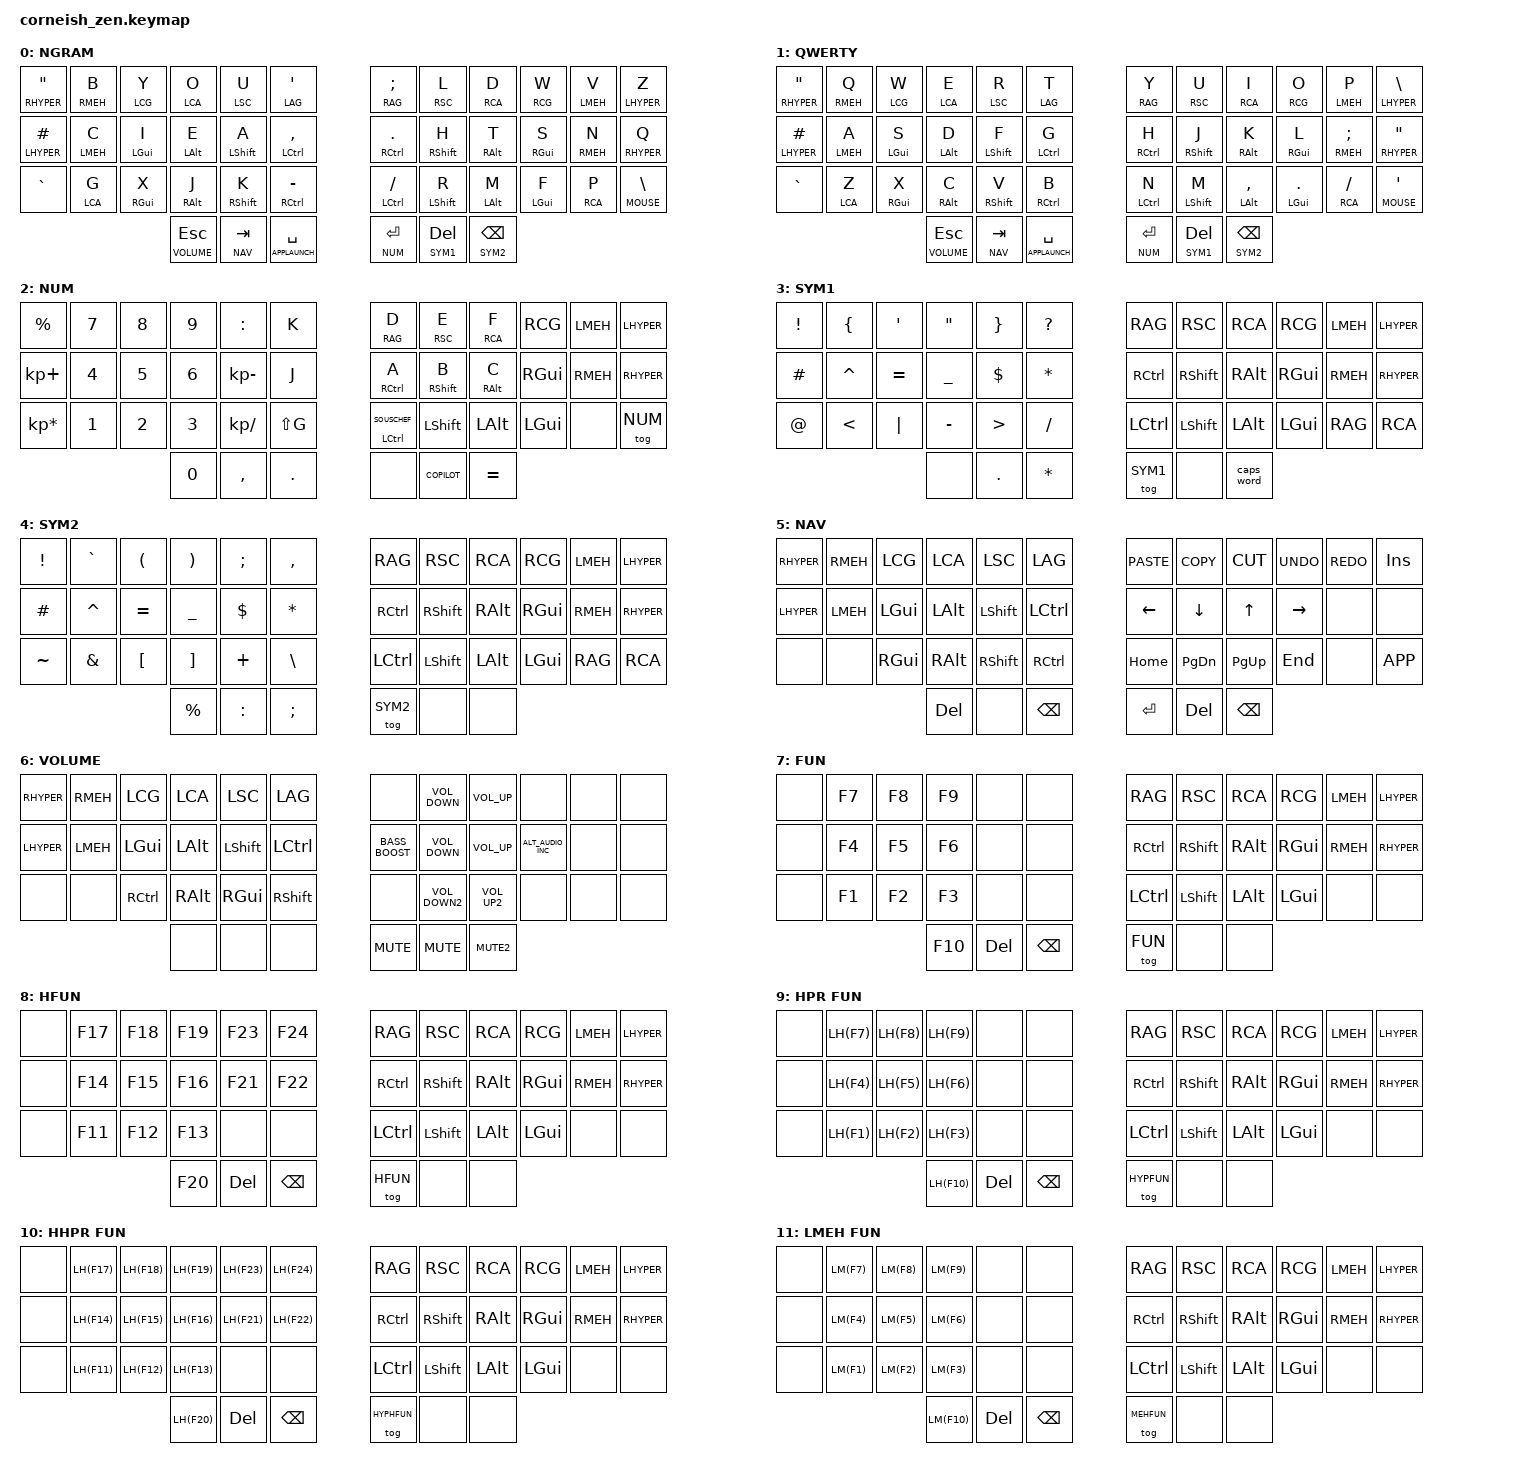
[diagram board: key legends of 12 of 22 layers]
/*
*
* Copyright (c) 2024  Hans Kruse
* Based on a configuration (c) 2023 Darryl deHaan
* SPDX-License-Identifier: MIT
*
*/

#include <behaviors.dtsi>
#include <dt-bindings/zmk/keys.h>
#include <dt-bindings/zmk/bt.h>
#include <dt-bindings/zmk/mouse.h>
#include <dt-bindings/zmk/outputs.h>
#include <dt-bindings/zmk/ext_power.h>
#include "numpad_extra_keys.h"
#include "consumer_extra_keys.h"
#include "custom_modifiers.h"

#define COPILOT  LSGK(F23)
#define SOUSCHEF RCAK(F24)


// layers
#define DEFAULT         0
#define NGRAM           0
#define QWERTY          1
#define NUM             2
#define SYM1            3
#define SYM2            4
#define NAV             5
#define VOLUME          6 
#define FUN             7
#define HFUN            8
#define HYPFUN          9
#define HYPHFUN        10
#define MEHFUN         11
#define MEHHFUN        12
#define MOUSE          13
#define CONFIG         14
#define POWER          15
#define DISPLAY        16
#define INTERNATIONAL  17
#define LANGUAGE       18
#define APPLAUNCH      19
#define CONSUMER       20
#define EMPTYLAYER     21

/ {
  chosen {
    zmk,matrix_transform = &default_transform;
    //zmk,matrix_transform = &five_column_transform;
  };
};

/*
 * Key numbering cheat sheet:
 * 
 * 0     1  2  3  4  5    6  7  8  9  10 11
 * TAB   Q  W  E  R  T    Y  U  I  O  P  BKSP
 * 
 * 12    13 14 15 16 17   18 19 20 21 22 23
 * Ctrl  A  S  D  F  G    H  J  K  L  ;  SQT
 *  
 * 24    25 26 27 28 29   30 31 32 33 34 35
 * Shift Z  X  C  V  B    N  M  ,  .  /  ESQ
 *
 *          36  37 38     39     40   41
 *          Win UP SPC    ENTER  DOWN ALT
 */
 
#define KEYS_L 0 1 2 3 4 5 12 13 14 15 16 17 24 25 26 27 28 29
#define KEYS_R 5 6 8 9 10 11 18 19 20 21 22 23 30 31 32 33 34 35
#define THUMBS_L 36 37 38
#define THUMBS_R 39 40 41

#define HM_TAPPING_TERM 200
#define HM_TAPPING_TERM_FAST 175
#define HM_PRIOR_IDLE 125
#define HM_QUICK_TAP 150

 / {
    	combos {
        	compatible = "zmk,combos";

		combo_symbol1 {
            		layers = <NGRAM QWERTY SYM1>;
            		timeout-ms = <25>;
            		key-positions = <39 40>;
            		bindings = <&tog SYM1>;
        	};

		combo_symbol2 {
            		layers = <NGRAM QWERTY SYM2>;
            		timeout-ms = <25>;
            		key-positions = <39 41>;
            		bindings = <&tog SYM2>;
        	};

		combo_num {
            		layers = <NGRAM QWERTY NUM>;
            		timeout-ms = <25>;
            		key-positions = <39 35>;
            		bindings = <&tog NUM>;
        	};

		combo_config {
            		layers = <NGRAM QWERTY CONFIG>;
            		timeout-ms = <25>;
            		key-positions = <24 35>;
            		bindings = <&tog CONFIG>;
        	};

		combo_volume {
            		layers = <NGRAM QWERTY VOLUME>;
            		timeout-ms = <25>;
            		key-positions = <24 11>;
            		bindings = <&tog VOLUME>;
        	};

		combo_display {
            		layers = <NGRAM QWERTY DISPLAY>;
            		timeout-ms = <25>;
            		key-positions = <24 6>;
            		bindings = <&tog DISPLAY>;
        	};

		combo_language {
            		layers = <NGRAM QWERTY LANGUAGE>;
            		timeout-ms = <25>;
            		key-positions = <0 11>;
            		bindings = <&tog LANGUAGE>;
        	};

		combo_international {
            		layers = <NGRAM QWERTY INTERNATIONAL>;
            		timeout-ms = <25>;
            		key-positions = <0 35>;
            		bindings = <&tog INTERNATIONAL>;
        	};

		combo_function_keys {
            		layers = <NGRAM QWERTY FUN>;
            		timeout-ms = <25>;
            		key-positions = <0 30>;
            		bindings = <&tog FUN>;
        	};

		combo_high_function_keys {
            		layers = <NGRAM QWERTY HFUN>;
            		timeout-ms = <25>;
            		key-positions = <0 18>;
            		bindings = <&tog HFUN>;
        	};

		combo_hyper_function_keys {
            		layers = <NGRAM QWERTY HYPFUN>;
            		timeout-ms = <25>;
            		key-positions = <12 31>;
            		bindings = <&tog HYPFUN>;
        	};

		combo_hyper_high_function_keys {
            		layers = <NGRAM QWERTY HYPHFUN>;
            		timeout-ms = <25>;
            		key-positions = <12 19>;
            		bindings = <&tog HYPHFUN>;
        	};

		combo_meh_function_keys {
            		layers = <NGRAM QWERTY MEHFUN>;
            		timeout-ms = <25>;
            		key-positions = <24 32>;
            		bindings = <&tog MEHFUN>;
        	};

		combo_meh_high_function_keys {
            		layers = <NGRAM QWERTY MEHHFUN>;
            		timeout-ms = <25>;
            		key-positions = <24 20>;
            		bindings = <&tog MEHHFUN>;
        	};

    	};
	behaviors {
		hl: homerow_mods_left {
			compatible = "zmk,behavior-hold-tap";
			#binding-cells = <2>;
			bindings = <&kp>, <&kp>;
			flavor = "balanced";
			tapping-term-ms = <HM_TAPPING_TERM_FAST>;
			quick-tap-ms = <HM_QUICK_TAP>;
			require-prior-idle-ms = <HM_PRIOR_IDLE>;
			hold-trigger-key-positions = <KEYS_R THUMBS_R>;
	  	};
		hr: homerow_mods_right {
			compatible = "zmk,behavior-hold-tap";
			#binding-cells = <2>;
			bindings = <&kp>, <&kp>;
			flavor = "balanced";
			tapping-term-ms = <HM_TAPPING_TERM_FAST>;
			quick-tap-ms = <HM_QUICK_TAP>;
			require-prior-idle-ms = <HM_PRIOR_IDLE>;
			hold-trigger-key-positions = <KEYS_L THUMBS_L>;
	  	};

	};

        keymap {
                compatible = "zmk,keymap";

                default_layer {
                        label = "NGRAM";
// ---------------------------------------------------------------------------------------------------------------------------------------------------------------------------------------------------------------------------------------------
// |          DQT   |         B  |            Y  |           O   |            U   |               SQT   |                       |             SEMI |            L   |            D    |              W  |            V  |            Z         |
// |          HASH  |         C  |            I  |           E   |            A   |               COMMA |                       |             DOT  |            H   |            T    |              S  |            N  |            Q         |
// |          GRAVE |         G  |            X  |           J   |            K   |               MINUS |                       |             FSLH |            R   |            M    |              F  |            P  |            BACKSLASH |       
//                                               |           ESC |            TAB |               SPACE |                       |             RET  |            DEL |            BSPC |
                        bindings = <
   &hl RHYPER DQT    &hl RMEH B   &hl LCG     Y    &hl LCA    O    &hl LSC    U     &hl LAG       SQT                             &hr RAG     SEMI   &hr RSC    L     &hr RCA    D      &hr RCG      W    &hr LMEH   V    &hr LHYPER Z 
   &hl LHYPER HASH   &hl LMEH C   &hl LGUI    I    &hl LALT   E    &hl LSHFT  A     &hl LCTRL     COMMA                           &hr RCTRL   DOT    &hr RSHFT  H     &hr RALT   T      &hr RGUI     S    &hr RMEH   N    &hr RHYPER Q
   &kp        GRAVE  &hl LCA  G   &hl RGUI    X    &hl RALT   J    &hl RSHFT  K     &hl RCTRL     MINUS                           &hr LCTRL   FSLH   &hr LSHFT  R     &hr LALT   M      &hr LGUI     F    &hr RCA    P    &lt MOUSE  BACKSLASH 
                                                   &lt VOLUME ESC  &lt NAV    TAB   &lt APPLAUNCH SPACE                           &lt NUM     RET    &lt SYM1   DEL   &lt SYM2   BSPC 
                        >;
                };

                qwerty_layer {
                        label = "QWERTY";
// ------------------------------------------------------------------------------------------------------------------------------------------------------------------------------------------------------------------------------------------
// |          DQT   |         Q  |            W  |           E   |            R   |               T     |                       |             Y   |            U   |            I    |              O  |            P  |            \        |
// |          HASH  |         A  |            S  |           D   |            F   |               G     |                       |             H   |            J   |            K    |              L  |            ;  |            "        |
// |          GRAVE |         Z  |            X  |           C   |            V   |               B     |                       |             N   |            M   |            ,    |              .  |            /  |            '        |       
//                                               |           ESC |            TAB |               SPACE |                       |             RET |            DEL |            BSPC |
                        bindings = <
   &hl RHYPER DQT    &hl RMEH Q   &hl LCG     W    &hl LCA    E    &hl LSC    R     &hl LAG       T                               &hr RAG     Y     &hr RSC    U     &hr RCA    I      &hr RCG      O    &hr LMEH   P    &hr LHYPER BACKSLASH
   &hl LHYPER HASH   &hl LMEH A   &hl LGUI    S    &hl LALT   D    &hl LSHFT  F     &hl LCTRL     G                               &hr RCTRL   H     &hr RSHFT  J     &hr RALT   K      &hr RGUI     L    &hr RMEH   SEMI &hr RHYPER DQT
   &kp        GRAVE  &hl LCA  Z   &hl RGUI    X    &hl RALT   C    &hl RSHFT  V     &hl RCTRL     B                               &hr LCTRL   N     &hr LSHFT  M     &hr LALT   COMMA  &hr LGUI     DOT  &hr RCA    FSLH &lt MOUSE  SQT 
                                                   &lt VOLUME ESC  &lt NAV    TAB   &lt APPLAUNCH SPACE                           &lt NUM     RET   &lt SYM1   DEL   &lt SYM2   BSPC 
                        >;
                };


                number_layer {
                        label = "NUM";
// ------------------------------------------------------------------------------------------------------------------------------------------------------------------------------------------------------------------------
// |   %           |     7        |     8        |     9        |     :        | k        |                                     |          D        |           E       |          F |           |      LMEH |    LHYPER  |
// |   +           |     4        |     5        |     6        |     -        | j        |                                     |          A        |           B       |          C |           |      RMEH |    RHYPER  |
// |   *           |     1        |     2        |     3        |     /        | G        |                                     |          SOUSCHEF |                   |            |           |           |            |
//                                               |     0        |     ,        | .        |                                     |                   |           COPILOT |          = |
                            bindings = <
   &kp PERCENT       &kp NUMBER_7   &kp NUMBER_8   &kp NUMBER_9   &kp COLON      &kp K                                            &mt RAG   D          &mt RSC   E          &mt RCA  F    &kp RCG     &kp LMEH  &kp LHYPER
   &kp KP_PLUS       &kp NUMBER_4   &kp NUMBER_5   &kp NUMBER_6   &kp KP_MINUS   &kp J                                            &mt RCTRL A          &mt RSHFT B          &mt RALT C    &kp RGUI    &kp RMEH  &kp RHYPER
   &kp KP_ASTERISK   &kp NUMBER_1   &kp NUMBER_2   &kp NUMBER_3   &kp KP_SLASH   &kp LS(G)                                        &mt LCTRL SOUSCHEF   &kp LSHFT            &kp LALT      &kp LGUI    &none     &tog NUM
                                                   &kp NUMBER_0   &kp COMMA      &kp DOT                                          &none                &kp        COPILOT   &kp      EQL      
                        >;
                };

                symbols_layer1 {
                        label = "SYM1";
// ---------------------------------------------------------------------------------------------------------------------------------------------------------------------------------------------------------
// |   !    |     {    |     '    |     "     |     }    |      ?        |                                                      |      RAG    |     RSC   |      RCA  |     RCG   |     LMEH |     LHYPER  |
// |   #    |     ^    |     =    |     _     |     $    |      *        |                                                      |      RCTRL  |     RSHFT |      RALT |     RGUI  |     RMEH |     RHYPER  |
// |   @    |     <    |    "|"   |     -     |     >    |      /        |                                                      |      LCTRL  |     LSHFT |      LALT |     LGUI  |     RAG  |     RCA     |
//                                |           |     .    |      *        |                                                      |             |           | CAPS WORD |
                       bindings = <
   &kp EXCL   &kp LBRC   &kp SQT    &kp DQT     &kp RBRC    &kp QMARK                                                             &kp  RAG    &kp   RSC     &kp   RCA   &kp RCG     &kp LMEH   &kp LHYPER
   &kp HASH   &kp CARET  &kp EQUAL  &kp UNDER   &kp DOLLAR  &kp ASTERISK                                                          &kp  RCTRL  &kp   RSHFT   &kp   RALT  &kp RGUI    &kp RMEH   &kp RHYPER
   &kp AT     &kp LT     &kp PIPE   &kp MINUS   &kp GT      &kp SLASH                                                             &kp  LCTRL  &kp   LSHFT   &kp   LALT  &kp LGUI    &kp RAG    &kp RCA
                                    &none       &kp DOT     &kp ASTERISK                                                          &tog SYM1   &none         &caps_word      
                        >;
                };
                symbols_layer2 {
                        label = "SYM2";
// ----------------------------------------------------------------------------------------------------------------------------------------------------------------------------------------------------------
// |   !    |     `     |      (   |     )       |     ;      |     ,         |                                                 |      RAG    |       RSC   |       RCA  |     RCG   |    LMEH |    LHYPER  |
// |   #    |     ^     |     =    |     _       |     $      |     *         |                                                 |      RCTRL  |       RSHFT |       RALT |     RGUI  |    RMEH |    RHYPER  |
// |   ~    |     &     |     [    |     ]       |     +      |     \         |                                                 |      LCTRL  |       LSHFT |       LALT |     LGUI  |    RAG  |    RCA     |
//                                 |     %       |     :      |     ;         |                                                 |             |             |            |
                       bindings = <
   &kp EXCL   &kp GRAVE   &kp LPAR   &kp RPAR      &kp SEMI     &kp COMMA                                                         &kp  RAG      &kp   RSC     &kp   RCA    &kp RCG    &kp LMEH  &kp LHYPER
   &kp HASH   &kp CARET   &kp EQUAL  &kp UNDER     &kp DOLLAR   &kp ASTERISK                                                      &kp  RCTRL    &kp   RSHFT   &kp   RALT   &kp RGUI   &kp RMEH  &kp RHYPER
   &kp TILDE  &kp AMPS    &kp LBKT   &kp RBKT      &kp PLUS     &kp BACKSLASH                                                     &kp  LCTRL    &kp   LSHFT   &kp   LALT   &kp LGUI   &kp RAG   &kp RCA
                                     &kp PERCENT   &kp COLON    &kp SEMI                                                          &tog SYM2     &none         &none      
                        >;
                };

                nav_layer {
                        label = "NAV";
// --------------------------------------------------------------------------------------------------------------------------------------------------------------------------------------------------------------------------
// |       RHYPER  |       RMEH   |     LCG   |     LCA  |       LSC   |     LAG   |                                            |     PASTE   |     COPY      |     CUT     |     UNDO   |       REDO   |            INS    |
// |       LHYPER  |       LMEH   |     LGUI  |     LALT |       LSHFT |     LCTRL |                                            |     LEFT    |     DOWN      |     UP      |     RIGHT  |              |                   |
// |               |              |     RGUI  |     RALT |       RSHFT |     RCTRL |                                            |     HOME    |     PAGE_DOWN |     PAGE_UP |     END    |              |            K_APP  |       
//                                            |     DEL  |             |     BSPC  |                                            |     RET     |     DEL       |     BSPC    |
                        bindings = <
     &kp   RHYPER    &kp   RMEH     &kp LCG     &kp LCA    &kp   LSC     &kp LAG                                                  &kp K_PASTE   &kp K_COPY      &kp K_CUT     &kp K_UNDO   &kp   K_REDO   &kp        INS
     &kp   LHYPER    &kp   LMEH     &kp LGUI    &kp LALT   &kp   LSHFT   &kp LCTRL                                                &kp LEFT      &kp DOWN        &kp UP        &kp RIGHT    &none          &none
     &none           &none          &kp RGUI    &kp RALT   &kp   RSHFT   &kp RCTRL                                                &kp HOME      &kp PAGE_DOWN   &kp PAGE_UP   &kp END      &none          &kp        K_APP
                                                &kp DEL    &none         &kp BSPC                                                 &kp RET       &kp DEL         &kp BSPC      
                        >;
                };

                volume_layer {
                        label = "VOLUME";
// ----------------------------------------------------------------------------------------------------------------------------------------------------------------------------------------------------------------------------------
// |       RHYPER |      RMEH |     LCG   |       LCA  |       LSC   |     LAG   |                                              |                    |     K_VOLUME_DOWN  |     K_VOlUME_UP  |                       |              |                |
// |       LHYPER |      LMEH |     LGUI  |       LALT |       LSHFT |     LCTRL |                                              |       C_BASS_BOOST |     C_VOLUME_DOWN  |     C_VOLUME_UP  |       C_ALT_AUDIO_INC |              |                |
// |              |           |     RCTRL |       RALT |       RGUI  |     RSHFT |                                              |                    |     K_VOLUME_DOWN2 |     K_VOlUME_UP2 |                       |              |                |      
//                                        |            |             |           |                                              |       K_MUTE       |     C_MUTE         |     K_MUTE2      |
                        bindings = <
     &kp   RHYPER   &kp  RMEH   &kp LCG     &kp   LCA    &kp   LSC   &kp   LAG                                                    &none                &kp K_VOLUME_DOWN    &kp K_VOLUME_UP    &none                   &none  &none 
     &kp   LHYPER   &kp  LMEH   &kp LGUI    &kp   LALT   &kp   LSHFT &kp   LCTRL                                                  &kp   C_BASS_BOOST   &kp C_VOLUME_DOWN    &kp C_VOLUME_UP    &kp   C_ALT_AUDIO_INC   &none  &none
     &none          &none       &kp RCTRL   &kp   RALT   &kp   RGUI  &kp   RSHFT                                                  &none                &kp K_VOLUME_DOWN2   &kp K_VOLUME_UP2   &none                   &none  &none
                                            &none        &none       &none                                                        &kp   K_MUTE         &kp C_MUTE           &kp K_MUTE2
                        >;
                };

                fun_layer {
                        label = "FUN";
// --------------------------------------------------------------------------------------------------------------------------------------------------------------------------------------------------------------
// |       |     F7 |   F8 |     F9  |         |            |                                                                   |      RAG    |       RSC   |     RCA  |      RCG  |       LMEH |       LHYPER  |
// |       |     F4 |   F5 |     F6  |         |            |                                                                   |      RCTRL  |       RSHFT |     RALT |      RGUI |       RMEH |       RHYPER  |
// |       |     F1 |   F2 |     F3  |         |            |                                                                   |      LCTRL  |       LSHFT |     LALT |      LGUI |            |               |
//                         |     F10 |     DEL |       BSPC |                                                                   | tog  FUN    |             |          |
                         bindings = <
     &none   &kp F7 &kp F8 &kp   F9  &none       &none                                                                            &kp  RAG      &kp   RSC     &kp RCA     &kp RCG    &kp   LMEH   &kp   LHYPER
     &none   &kp F4 &kp F5 &kp   F6  &none       &none                                                                            &kp  RCTRL    &kp   RSHFT   &kp RALT    &kp RGUI   &kp   RMEH   &kp   RHYPER
     &none   &kp F1 &kp F2 &kp   F3  &none       &none                                                                            &kp  LCTRL    &kp   LSHFT   &kp LALT    &kp LGUI   &none        &none
                           &kp   F10 &kp   DEL   &kp   BSPC                                                                       &tog FUN      &none         &none     
                        >;
                };

                hfun_layer {
                        label = "HFUN";
// ----------------------------------------------------------------------------------------------------------------------------------------------------------------------------------------------------------------
// |       |     F17 |     F18 |       F19 |       F23  |       F24  |                                                          |      RAG    |       RSC   |       RCA  |      RCG  |       LMEH |       LHYPER  |
// |       |     F14 |     F15 |       F16 |       F21  |       F22  |                                                          |      RCTRL  |       RSHFT |       RALT |      RGUI |       RMEH |       RHYPER  |
// |       |     F11 |     F12 |       F13 |            |            |                                                          |      LCTRL  |       LSHFT |       LALT |      LGUI |            |               |
//                             |       F20 |        DEL |       BSPC |                                                          |  tog HFUN   |             |            |
                         bindings = <
     &none   &kp F17   &kp F18   &kp   F19   &kp   F23    &kp   F24                                                               &kp  RAG      &kp   RSC     &kp   RCA     &kp RCG    &kp   LMEH   &kp   LHYPER
     &none   &kp F14   &kp F15   &kp   F16   &kp   F21    &kp   F22                                                               &kp  RCTRL    &kp   RSHFT   &kp   RALT    &kp RGUI   &kp   RMEH   &kp   RHYPER
     &none   &kp F11   &kp F12   &kp   F13   &none        &none                                                                   &kp  LCTRL    &kp   LSHFT   &kp   LALT    &kp LGUI   &none        &none
                                 &kp   F20   &kp   DEL    &kp   BSPC                                                              &tog HFUN     &none         &none     
                        >;
                };

                hypfun_layer {
                        label = "HPR FUN";
// -----------------------------------------------------------------------------------------------------------------------------------------------------------------------------------------------------------------
// |       |        F7  |        F8  |        F9  |          |            |                                                     |       RAG    |       RSC   |       RCA  |      RCG  |       LMEH |       LHYPER  |
// |       |        F4  |        F5  |        F6  |          |            |                                                     |       RCTRL  |       RSHFT |       RALT |      RGUI |       RMEH |       RHYPER  |
// |       |        F1  |        F2  |        F3  |          |            |                                                     |       LCTRL  |       LSHFT |       LALT |      LGUI |            |               |
//                                   |        F10 |          |            |                                                     |              |             |            |
                         bindings = <
     &none   &kp LH(F7)   &kp LH(F8)   &kp LH(F9)   &none      &none                                                              &kp   RAG      &kp   RSC     &kp   RCA     &kp RCG    &kp   LMEH   &kp   LHYPER
     &none   &kp LH(F4)   &kp LH(F5)   &kp LH(F6)   &none      &none                                                              &kp   RCTRL    &kp   RSHFT   &kp   RALT    &kp RGUI   &kp   RMEH   &kp   RHYPER
     &none   &kp LH(F1)   &kp LH(F2)   &kp LH(F3)   &none      &none                                                              &kp   LCTRL    &kp   LSHFT   &kp   LALT    &kp LGUI   &none        &none
                                       &kp LH(F10)  &kp   DEL  &kp   BSPC                                                         &tog  HYPFUN   &none         &none     
                        >;
                };

                hyphfun_layer {
                        label = "HHPR FUN";
// ---------------------------------------------------------------------------------------------------------------------------------------------------------------------------------------------------------------
// |       |        F17  |        F18 |        F19 |          F23 |           F24 |                                             |       RAG     |      RSC   |     RCA  |      RCG  |       LMEH |       LHYPER  |
// |       |        F14  |        F15 |        F16 |          F21 |           F22 |                                             |       RCTRL   |      RSHFT |     RALT |      RGUI |       RMEH |       RHYPER  |
// |       |        F11  |        F12 |        F13 |              |               |                                             |       LCTRL   |      LSHFT |     LALT |      LGUI |            |               |
//                                    |        F20 |          DEL |        BSPC   |                                             | tog   HYPHFUN |            |          |
                         bindings = <
     &none   &kp LH(F17)   &kp LH(F18)  &kp LH(F19)   &kp   LH(F23)  &kp   LH(F24)                                                &kp  RAG        &kp   RSC     &kp RCA     &kp RCG    &kp   LMEH   &kp   LHYPER
     &none   &kp LH(F14)   &kp LH(F15)  &kp LH(F16)   &kp   LH(F21)  &kp   LH(F22)                                                &kp  RCTRL      &kp   RSHFT   &kp RALT    &kp RGUI   &kp   RMEH   &kp   RHYPER
     &none   &kp LH(F11)   &kp LH(F12)  &kp LH(F13)   &none          &none                                                        &kp  LCTRL      &kp   LSHFT   &kp LALT    &kp LGUI   &none        &none
                                        &kp LH(F20)   &kp   DEL      &kp   BSPC                                                   &tog HYPHFUN    &none         &none     
                        >;
                };

                mehfun_layer {
                        label = "LMEH FUN";
// -----------------------------------------------------------------------------------------------------------------------------------------------------------------------------------------------------------------
// |      |         F7  |        F8  |        F9   |           |           |                                                     |      RAG    |       RSC   |       RCA  |      RCG  |       LMEH |       LHYPER  |
// |      |         F4  |        F5  |        F6   |           |           |                                                     |      RCTRL  |       RSHFT |       RALT |      RGUI |       RMEH |       RHYPER  |
// |      |         F1  |        F2  |        F3   |           |           |                                                     |      LCTRL  |       LSHFT |       LALT |      LGUI |            |               |
//                                   |        F10  |       DEL |      BSPC |                                                     |  tog MEHFUN |             |            |
                         bindings = <
    &none    &kp LM(F7)   &kp LM(F8)   &kp LM(F9)    &none      &none                                                             &kp  RAG       &kp   RSC     &kp   RCA     &kp RCG    &kp   LMEH   &kp   LHYPER
    &none    &kp LM(F4)   &kp LM(F5)   &kp LM(F6)    &none      &none                                                             &kp  RCTRL     &kp   RSHFT   &kp   RALT    &kp RGUI   &kp   RMEH   &kp   RHYPER
    &none    &kp LM(F1)   &kp LM(F2)   &kp LM(F3)    &none      &none                                                             &kp  LCTRL     &kp   LSHFT   &kp   LALT    &kp LGUI   &none        &none
                                       &kp LM(F10)   &kp   DEL  &kp   BSPC                                                        &tog MEHFUN    &none         &none     
                        >;
                };

                mehhfun_layer {
                        label = "HLMEH FUN";
// ------------------------------------------------------------------------------------------------------------------------------------------------------------------------------------------------------------------- 
// |       |        F17  |        F18  |        F19  |          F23  |          F24  |                                          |       RAG     |       RSC    |       RCA  |      RCG  |       LMEH |       LHYPER  |
// |       |        F14  |        F15  |        F16  |          F21  |          F22  |                                          |       RCTRL   |       RSHFT  |       RALT |      RGUI |       RMEH |       RHYPER  |
// |       |        F11  |        F12  |        F13  |               |               |                                          |       LCTRL   |       LSHFT  |       LALT |      LGUI |            |               |
//                                     |        F20  |               |               |                                          |   tog MEHHFUN |              |            |
                         bindings = <
     &none   &kp LM(F17)   &kp LM(F18)   &kp LM(F19)   &kp   LM(F23)   &kp   LM(F24)                                              &kp  RAG        &kp   RSC     &kp   RCA     &kp RCG    &kp   LMEH   &kp   LHYPER
     &none   &kp LM(F14)   &kp LM(F15)   &kp LM(F16)   &kp   LM(F21)   &kp   LM(F22)                                              &kp  RCTRL      &kp   RSHFT   &kp   RALT    &kp RGUI   &kp   RMEH   &kp   RHYPER
     &none   &kp LM(F11)   &kp LM(F12)   &kp LM(F13)   &none           &none                                                      &kp  LCTRL      &kp   LSHFT   &kp   LALT    &kp LGUI   &none        &none
                                         &kp LM(F20)   &kp   DEL       &kp   BSPC                                                 &tog MEHHFUN    &none         &none     
                        >;
                };

                mouse_layer {
                        label = "MOUSE";
// ---------------------------------------------------------------------------------------------------------------------------------------------------------------------------------------------
// |        |         |            |          |         |            |                                                          |       |       |           |           |           |          |
// | LHYPER |         |      LGUI  |     LALT |   LSHFT | LCTRL      |                                                          |       |       |       MB1 |       MB3 |       MB4 |      MB5 |
// | LMEH   |         |      RGUI  |     RALT |   RSHFT | RCTRL      |                                                          |       |       |       MB2 |           |           |          |      
//                                 |          |         |            |                                                          |       |       |           |
                        bindings = <
   &none        &none  &none         &none      &none        &none                                                                &none   &none   &none       &none      &none       &none   
   &kp   LHYPER &none  &kp   LGUI    &kp LALT   &kp    LSHFT &kp   LCTRL                                                          &none   &none   &mkp  MB1   &mkp  MB3  &mkp   MB4  &mkp  MB5
   &kp   LMEH   &none  &kp   RGUI    &kp RALT   &kp    RSHFT &kp   RCTRL                                                          &none   &none   &mkp  MB2   &none      &none       &none
                            &none    &none       &none                                                                            &none   &none   &none      
                        >;
                };
                
                config_layer {
                        label = "CONFIG";
// -----------------------------------------------------------------------------------------------------------------------------------------------------------------------------------------------------------------------------------------
// | left reset     |       |        |               |               |                |                                         |      BT_CLR      |     BT_PRV      |     BT_NXT    |     BT_CLR_AL   |               | right reset       |
// | left bootloader|       |        |               |               |                |                                         |      BT_SEL 0    |     BT_SEL 1    |     BT_SEL 2  |     BT_SEL 3    |     BT_SEL 4  | right bootloader  | 
// | soft off       |       |        |               |               |       SOFT OFF |                                         |      BT_DISC 0   |     BT_DISC 1   |     BT_DISC 2 |     BIT_DISC 3  |     BT_DISC 4 |            EP_TOG |
//                                   |       OUT_USB |       OUT_BLE |       OUT_TOG  |                                         |      EP_TOG      |     EP_ON       |     EP_OFF    |
                         bindings = <
   &sys_reset  &none         &none     &none           &to   QWERTY    &to   NGRAM                                                &bt  BT_CLR        &bt BT_PRV        &bt BT_NXT      &bt BT_CLR_ALL    &none           &sys_reset 
   &bootloader &none         &none     &none           &none           &none                                                      &bt  BT_SEL 0      &bt BT_SEL 1      &bt BT_SEL 2    &bt BT_SEL 3      &bt BT_SEL 4    &bootloader
   &soft_off   &none         &none     &none           &none           &soft_off                                                  &bt  BT_DISC 0     &bt BT_DISC 1     &bt BT_DISC 2   &bt BT_DISC 3     &bt BT_DISC 4   &ext_power EP_TOG
                                       &out  OUT_USB   &out  OUT_BLE   &out  OUT_TOG                                              &tog CONFIG        &ext_power EP_ON  &ext_power EP_OFF      
                        >;
                };

                power_layer {
                        label = "POWER";
// --------------------------------------------------------------------------------------------------------------------------------------------------------------------------------------------------------
// |       |       |       |      |       |         |                                                                           |     C_RESET      |     K_POWER   |    C_POWER     |      |      |       |
// |       |       |       |      |       |         |                                                                           |     C_SLEEP_MODE |     K_SLEEP   |    C_SLEEP     |      |      |       | 
// |       |       |       |      |       |         |                                                                           |                  |               |                |      |      |       |
//                         |      |       |         |                                                                           |     K_LOCK       |     C_AL_LOCK |    C_AL_LOGOFF |
                         bindings = <
     &none   &none   &none  &none   &none   &none                                                                                 &kp C_RESET        &kp K_POWER    &kp K_POWER       &none  &none  &none 
     &none   &none   &none  &none   &none   &none                                                                                 &kp C_SLEEP_MODE   &kp K_SLEEP    &kp C_SLEEP       &none  &none  &none
     &none   &none   &none  &none   &none   &none                                                                                 &none              &none          &none             &none  &none  &none
                            &none   &none   &none                                                                                 &kp K_LOCK         &kp C_AL_LOCK  &kp C_AL_LOGOFF  
                        >;
                };



                display_layer {
                        label = "DISPLAY";
// -------------------------------------------------------------------------------------------------------------------------------------------------------------------------------------------------------------------------------------
// |       |       |       |       |       |       |                                                                            | toggle DISPLAY   |                  |                  |                  |                  |       |
// |       |       |       |       |       |       |                                                                            |       C_BRI_MIN  |        C_BRI_DEC |        C_BRI_INC |        C_BR_MAX  |       C_BRI_AUTO |       | 
// |       |       |       |       |       |       |                                                                            |                  |                  |                  |                  |                  |       |
//                         |       |       |       |                                                                            |       C_BKLT_TOG |        C_ASPECT  |        C_PIP     | 
                         bindings = <
     &none   &none   &none   &none   &none   &none                                                                                &tog  DISPLAY      &none              &none              &none              &none              &none 
     &none   &none   &none   &none   &none   &none                                                                                &kp   C_BRI_MIN    &kp    C_BRI_DEC   &kp    C_BRI_INC   &kp    C_BRI_MAX   &kp   C_BRI_AUTO   &none
     &none   &none   &none   &none   &none   &none                                                                                &none              &none              &none              &none              &none              &none
                             &none   &none   &none                                                                                &kp   C_BKLT_TOG   &kp    C_ASPECT    &kp    C_PIP 
                        >;
                };


                international_layer {
                        label = "INT";
// -----------------------------------------------------------------------------------------------------------------------------------------------------------------------------------------------------------------------
// |       |     INT7 |     INT8 |        INT9  |          |             |                                                      |       RAG         |        RSC    |      RCA  |      RCG  |       LMEH |       LHYPER  |
// |       |     INT4 |     INT5 |        INT6  |          |             |                                                      |       RCTRL       |        RSHFT  |      RALT |      RGUI |       RMEH |       RHYPER  |
// |       |     INT1 |     INT2 |        INT3  |          |             |                                                      |       LCTRL       |        LSHFT  |      LALT |      LGUI |            |               |
//                               |              |      TAB |       SPACE |                                                      |                   |               |           |
                         bindings = < 
     &none   &kp INT7   &kp INT8    &kp   INT9   &none       &none                                                                &kp   RAG            &kp   RSC     &kp   RCA     &kp RCG    &kp   LMEH   &kp   LHYPER
     &none   &kp INT4   &kp INT5    &kp   INT6   &none       &none                                                                &kp   RCTRL          &kp   RSHFT   &kp   RALT    &kp RGUI   &kp   RMEH   &kp   RHYPER
     &none   &kp INT1   &kp INT2    &kp   INT3   &none       &none                                                                &kp   LCTRL          &kp   LSHFT   &kp   LALT    &kp LGUI   &none        &none
                                    &none        &kp   TAB   &kp   SPACE                                                          &tog  INTERNATIONAL  &none         &none 
                        >;
                };

                language_layer {
                        label = "LANG";
// -------------------------------------------------------------------------------------------------------------------------------------------------------------------- ----------------------------------------------
// |       |     LANG7 |     LANG8 |       LANG9  |            |             |                                                  |       RAG      |       RSC   |       RCA  |      RCG  |       LMEH |       LHYPER  |
// |       |     LANG4 |     LANG5 |       LANG6  |            |             |                                                  |       RCTRL    |       RSHFT |       RALT |      RGUI |       RMEH |       RHYPER  |
// |       |     LANG1 |     LANG2 |       LANG3  |            |             |                                                  |       LCTRL    |       LSHFT |       LALT |      LGUI |            |               |
//                                 |              |        TAB |             |                                                  |                |             |       |
                         bindings = <
     &none   &kp LANG7   &kp LANG8   &kp   LANG9     &none       &none                                                            &kp   RAG        &kp   RSC     &kp   RCA     &kp RCG    &kp   LMEH   &kp   LHYPER
     &none   &kp LANG4   &kp LANG5   &kp   LANG6     &none       &none                                                            &kp   RCTRL      &kp   RSHFT   &kp   RALT    &kp RGUI   &kp   RMEH   &kp   RHYPER
     &none   &kp LANG1   &kp LANG2   &kp   LANG3     &none       &none                                                            &kp   LCTRL      &kp   LSHFT   &kp   LALT    &kp LGUI   &none        &none
                                     &none           &kp   TAB   &kp   SPACE                                                      &tog  LANGUAGE   &none         &none 
                        >;
                };

                application_launch_layer {
                        label = "APPL";
// -----------------------------------------------------------------------------------------------------------------------------------------------------------------------------------------------------------------------------------------------------------------------------------------------------------------------------------------------------------------
// |        C_AL_MY_COMPUTER |    C_AL_DOCUMENTS   |     C_AL_FILE_BROWSER |     C_AL_WWW                |     K_WWW             |      C_AL_CALCULATOR      |                        |     C_AL_IMAGE_BROWSER |     C_AL_NEWS         |     C_AL_TASK_MANAGER        |    C_AL_KEYBOARD_LAYOUT  |    C_AL_COMMAND_LINE                    |     C_AL_HELP         |
// |        C_AL_EMAIL       |    C_AL_CALENDAR    |     C_AL_CONTACTS     |     C_AL_INSTANT_MESSAGING  |     C_AL_NETWORK_CHAT |      C_AL_TEXT_EDITOR     |                        |     C_AL_AUDIO_BROWSER |     C_AL_VOICEMAIL    |     C_AL_AV_CAPTURE_PLAYBACK |    C_AL_THESAURUS        |    C_AL_TELEPHONY_DIALER                |     K_HELP            |
// |        C_AL_WORD        |    C_AL_SPREADSHEET |     C_AL_PRESENTATION |     C_AL_DATABASE           |     C_AL_JOURNAL      |      C_AL_GRAPHICS_EDITOR |                        |     C_AL_MOVIE_BROWSER |     C_AL_FINANCE      |     C_AL_SPELLCHECK          |    C_AL_GRAMMAR_CHECK    |    C_AL_CONTEXT_AWARE_DESKTOP_ASSISTANT |     C_AL_OEM_FEATURES |
//                                                 |     C_AL_PRESENTATION |     C_AL_PREV_TASK          |     C_AL_NEXT_TASK    |                           |                        |     C_AL_SCREEN_SAVER  |     C_AL_COMMAND_LINE |     C_AL_SELECT_TASK         |
                         bindings = <
   &kp      C_AL_MY_COMPUTER  &kp C_AL_DOCUMENTS     &kp C_AL_FILE_BROWSER   &kp C_AL_WWW                  &kp K_WWW               &kp  C_AL_CALCULATOR                                 &kp C_AL_IMAGE_BROWSER   &kp C_AL_NEWS           &kp C_AL_TASK_MANAGER         &kp C_AL_KEYBOARD_LAYOUT   &kp C_AL_CONTROL_PANEL                     &kp C_AL_HELP
   &mt LHYPER C_AL_EMAIL        &kp C_AL_CALENDAR      &kp C_AL_CONTACTS       &kp C_AL_INSTANT_MESSAGING    &kp C_AL_NETWORK_CHAT   &kp  C_AL_TEXT_EDITOR                                &kp C_AL_AUDIO_BROWSER   &kp C_AL_VOICEMAIL      &kp C_AL_AV_CAPTURE_PLAYBACK  &kp C_AL_THESAURUS         &kp C_AL_TELEPHONY_DIALER                  &kp K_HELP
   &mt LMEH C_AL_WORD         &kp C_AL_SPREADSHEET   &kp C_AL_PRESENTATION   &kp C_AL_DATABASE             &kp C_AL_JOURNAL        &kp  C_AL_GRAPHICS_EDITOR                            &kp C_AL_MOVIE_BROWSER   &kp C_AL_FINANCE        &kp C_AL_SPELLCHECK           &kp C_AL_GRAMMAR_CHECK     &kp C_AL_CONTEXT_AWARE_DESKTOP_ASSISTANT   &kp C_AL_OEM_FEATURES
                                                                             &kp C_AL_PREV_TASK            &kp C_AL_NEXT_TASK      &none                                                &kp C_AL_SCREEN_SAVER    &kp C_AL_COMMAND_LINE   &kp C_AL_SELECT_TASK 
                        >;
                };

                consumer_layer {
                        label = "CONSUMER";
// ----------------------------     ---------------------------------------------------------------------------------------------------
// |       |      |      |     |      |         |                                          |      |      |      |      |      |       |
// |       |      |      |     |      |         |                                          |      |      |      |      |      |       | 
// |       |      |      |     |      |         |                                          |      |      |      |      |      |       |
//                       |     |      |         |                                          |      |      |      |
                         bindings = <
   &kp   AT  &none       &none  &none  &none  &none                                          &none  &none  &none  &none  &none  &none 
   &none     &none       &none  &none  &none  &none                                          &none  &none  &none  &none  &none  &none
   &none     &none       &none  &none  &none  &none                                          &none  &none  &none  &none  &none  &none
                                &none  &none  &none                                          &none  &none  &none 
                        >;
                };

                empty_layer {
                        label = "empty";
// ------------------------------------------------------------------------------------------------------------------------------
// |     |      |      |     |      |         |                                      |      |      |      |      |      |       |
// |     |      |      |     |      |         |                                      |      |      |      |      |      |       | 
// |     |      |      |     |      |         |                                      |      |      |      |      |      |       |
//                     |     |      |         |                                      |      |      |      |
                         bindings = <
   &none  &none  &none  &none  &none  &none                                            &none  &none  &none  &none  &none  &none 
   &none  &none  &none  &none  &none  &none                                            &none  &none  &none  &none  &none  &none
   &none  &none  &none  &none  &none  &none                                            &none  &none  &none  &none  &none  &none
                        &none  &none  &none                                            &none  &none  &none 
                        >;
                };
        };
};
